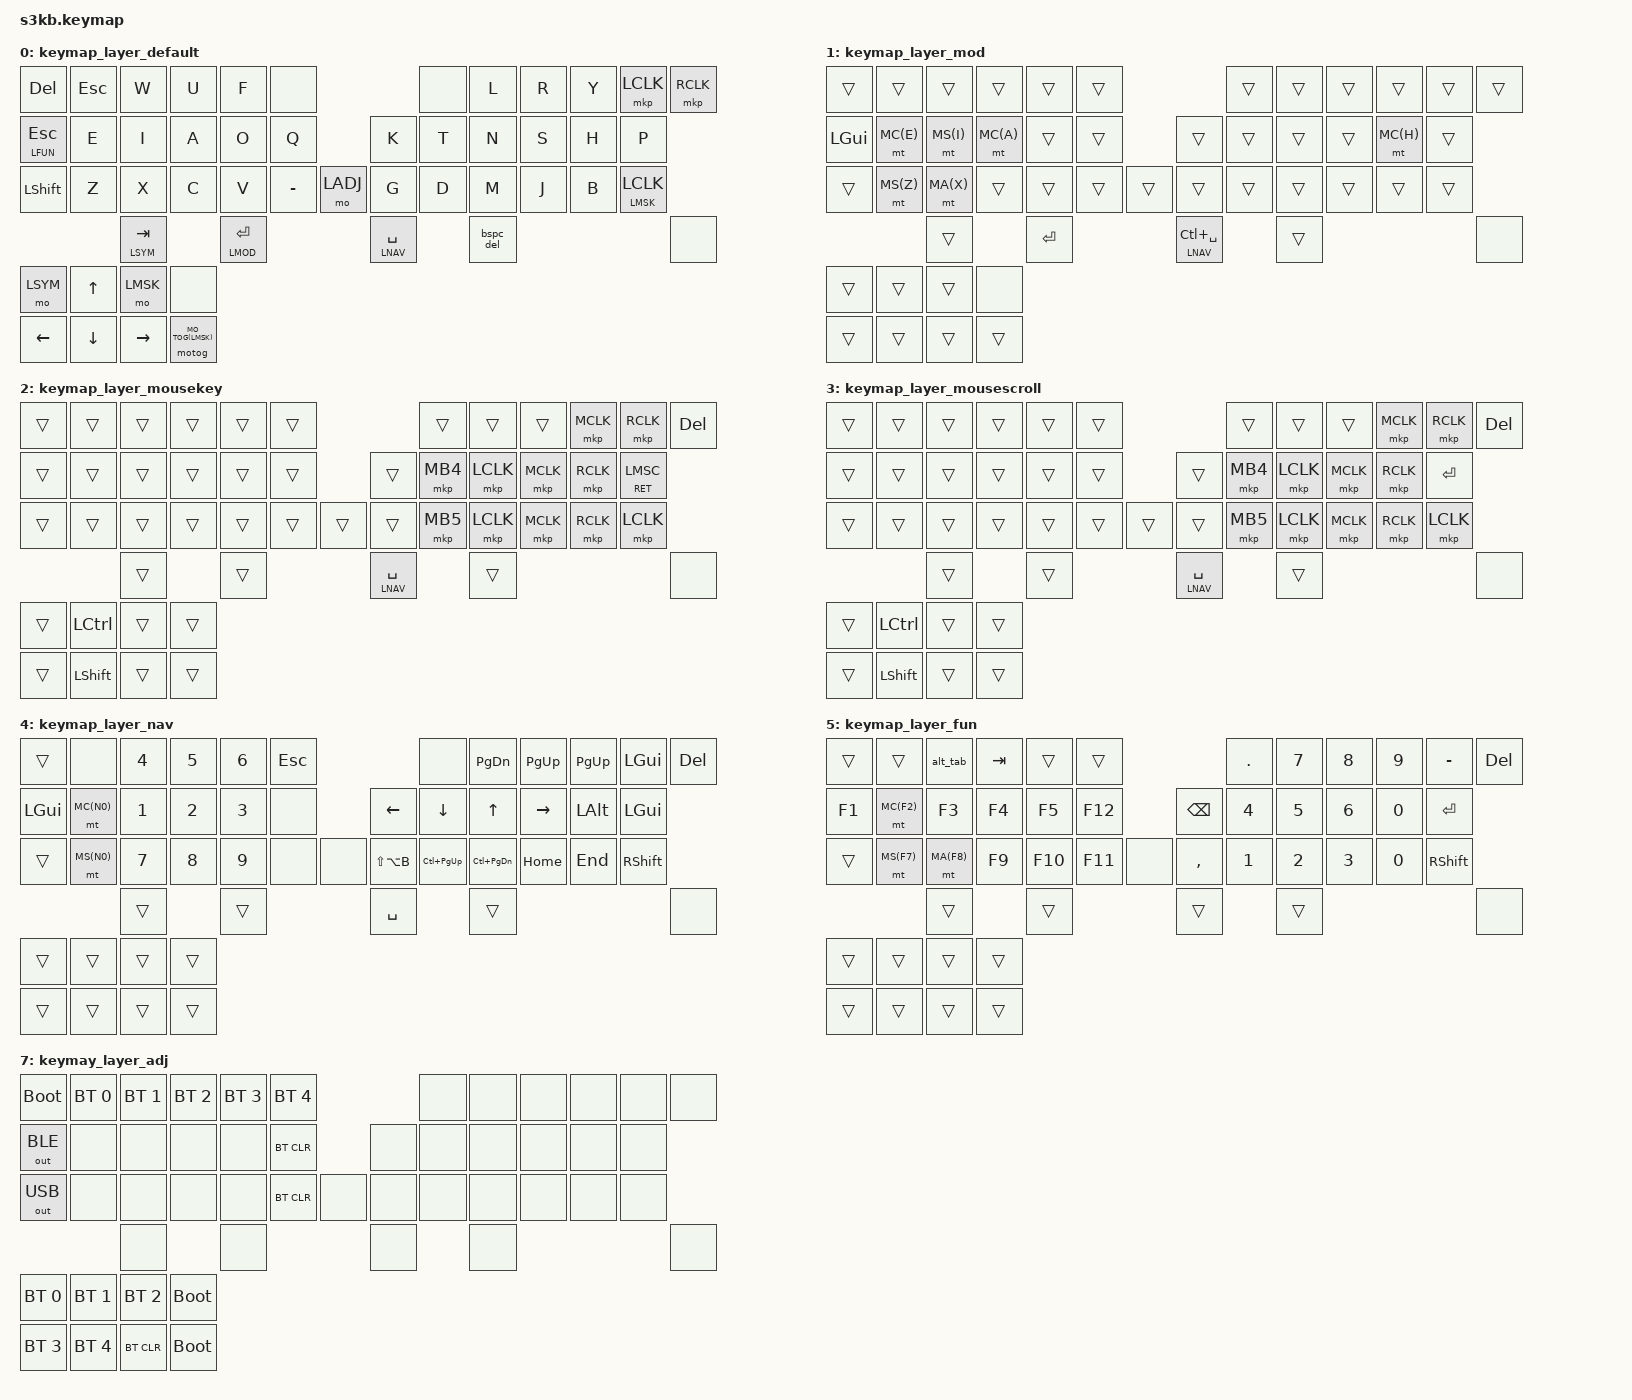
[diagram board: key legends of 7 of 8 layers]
#include <behaviors.dtsi>
#include <dt-bindings/zmk/keys.h>
#include <dt-bindings/zmk/bt.h>
#include <dt-bindings/zmk/outputs.h>
#include <dt-bindings/zmk/mouse.h>


/*
        ////////////////////
        // layer settings //
        ////////////////////
*/
#define LDEF 0
#define LMOD 1
#define LMSK 2
#define LMSC 3
#define LNAV 4
#define LFUN 5
#define LSYM 6
#define LADJ 7
/{
    keymap {
        compatible = "zmk,keymap";
        keymap_layer_default:keymap_layer_default{};
        keymap_layer_mod:keymap_layer_mod{};
        keymap_layer_mousekey:keymap_layer_mousekey{};
        keymap_layer_mousescroll:keymap_layer_mousescroll{};
        keymap_layer_nav:keymap_layer_nav{};
        keymap_layer_fun:keymap_layer_fun{};
        keymap_layer_sym:keymap_layer_sym{};
        keymay_layer_adj:keymay_layer_adj{};
    };
};


/*
        //////////////
        // encoders //
        //////////////
*/
/ {
    encoders: encoders {
        compatible = "zmk,keymap-sensors";
        sensors = <&left_encoder &mid_encoder &right_encoder>;
        left_config{
            triggers-per-rotation = <7>;
        };
        mid_config{
            triggers-per-rotation = <24>;
        };
        right_config{
            triggers-per-rotation = <24>;
        };
    };
};

// scroll behavior for encoder
#define ZMK_MOUSE_ENC_SCRL_VAL 70
#define SCRL_ENC_UP MOVE_Y(ZMK_MOUSE_ENC_SCRL_VAL)
#define SCRL_ENC_DOWN MOVE_Y(-ZMK_MOUSE_ENC_SCRL_VAL)
#define SCRL_ENC_LEFT MOVE_X(-ZMK_MOUSE_ENC_SCRL_VAL)
#define SCRL_ENC_RIGHT MOVE_X(ZMK_MOUSE_ENC_SCRL_VAL)
#define ZMK_MOUSE_ENC_SCRL_FAST_VAL 140
#define SCRL_ENC_FAST_UP MOVE_Y(ZMK_MOUSE_ENC_SCRL_FAST_VAL)
#define SCRL_ENC_FAST_DOWN MOVE_Y(-ZMK_MOUSE_ENC_SCRL_FAST_VAL)
#define SCRL_ENC_FAST_LEFT MOVE_X(-ZMK_MOUSE_ENC_SCRL_FAST_VAL)
#define SCRL_ENC_FAST_RIGHT MOVE_X(ZMK_MOUSE_ENC_SCRL_FAST_VAL)
/{
    behaviors{
        scroll_enc_du: scroll_enc_du {
            compatible = "zmk,behavior-sensor-rotate";
            #sensor-binding-cells = <0>;
            bindings = <&msc SCRL_ENC_DOWN>, <&msc SCRL_ENC_UP>;
            tap-ms = <20>;
        };
        scroll_enc_fast_du: scroll_enc_fast_du {
            compatible = "zmk,behavior-sensor-rotate";
            #sensor-binding-cells = <0>;
            bindings = <&msc SCRL_ENC_FAST_DOWN>, <&msc SCRL_ENC_FAST_UP>;
            tap-ms = <20>;
        };
        scroll_enc_rl: scroll_enc_rl {
            compatible = "zmk,behavior-sensor-rotate";
            #sensor-binding-cells = <0>;
            bindings = <&msc SCRL_ENC_RIGHT>, <&msc SCRL_ENC_LEFT>;
            tap-ms = <20>;
        };
    };
};

/*
        //////////////////////////
        // custom key behaviors //
        //////////////////////////
*/
// macro for mod tap
#define MC(X) LCTRL X
#define MS(X) LSHFT X
#define MA(X) LALT X
#define MG(X) LGUI X

&mt {
    tapping-term-ms = <175>;
    flavor = "tap-preferred";
};
&lt {
    tapping-term-ms = <175>;
    flavor = "balanced";
};
&sk {
    quick-release;
};
&caps_word {
    continue-list = <UNDERSCORE MINUS BACKSPACE>;
};
#define MO_TOG(X) X X
/ {
    behaviors {
        // original behaviors
        smo: sticky_key_and_mo {
            // &smo LFUN LSHFT : tap to sticky shift, hold to function layer
            compatible = "zmk,behavior-hold-tap";
            #binding-cells = <2>;
            flavor = "hold-preferred";
            tapping-term-ms = <200>;
            bindings = <&mo>, <&sk>;
        };
        bspc_del: bspc_and_del{
            compatible = "zmk,behavior-mod-morph";
            #binding-cells = <0>;
            bindings = <&kp BSPC>, <&kp DEL>;
            mods = <(MOD_LSFT|MOD_RSFT)>;
        };
 
        // behaviors for mouse
        motog: behavior_mo_tog {
            compatible = "zmk,behavior-hold-tap";
            #binding-cells = <2>;
            flavor = "hold-preferred";
            tapping-term-ms = <200>;
            bindings = <&mo>, <&tog>;
        };
        mlt: mouse_layer_tap {
            compatible = "zmk,behavior-hold-tap";
            #binding-cells = <2>;
            flavor = "tap-preferred";
            tapping-term-ms = <200>;
            bindings = <&mo>, <&mkp>;
        };

        // behaviors for mod layer
        lth: layer_tap_hold_flavor {
            compatible = "zmk,behavior-hold-tap";
            #binding-cells = <2>;
            flavor = "hold-preferred";
            tapping-term-ms = <200>;
            bindings = <&mo>, <&kp>;
        };
        lm: momentally_layer_and_modifier {
            // activate momentally layer and press (modifier) key
            // &lm LMOD LCTRL : activate modifier layer with LCTRL hold
            compatible = "zmk,behavior-macro-two-param";
            wait-ms = <0>;
            tap-ms = <0>;
            #binding-cells = <2>;
            bindings
                = <&macro_param_1to1>
                , <&macro_press &mo MACRO_PLACEHOLDER>
                , <&macro_param_2to1>
                , <&macro_press &kp MACRO_PLACEHOLDER>
                , <&macro_pause_for_release>
                , <&macro_param_2to1>
                , <&macro_release &kp MACRO_PLACEHOLDER>
                , <&macro_param_1to1>
                , <&macro_release &mo MACRO_PLACEHOLDER>
                ;
        };
    };
    macros {
        // alt+tab on tap, continue to press alt on hold. 
        alt_tab: alt_tab {
            compatible = "zmk,behavior-macro";
            #binding-cells = <0>;
            wait-ms = <0>;
            tap-ms = <0>;
            bindings
                = <&macro_press &kp LALT>
                , <&macro_tap &kp TAB>
                , <&macro_pause_for_release>
                , <&macro_release &kp LALT>
                ;
        };
    };
};



/*
        ////////////
        // combos //
        ////////////
*/
/{
    combos{
        compatible = "zmk,combos";
        timeout-ms = <200>;

        // key-position = row*7 + col
        //    RC(0,0) RC(0,1) RC(0,2) RC(0,3) RC(0,4) RC(0,5)         RC(0,6) RC(1,0) RC(1,1) RC(1,2) RC(1,3) RC(1,4)
        //    RC(1,5) RC(1,6) RC(2,0) RC(2,1) RC(2,2) RC(2,3)         RC(2,4) RC(2,5) RC(2,6) RC(3,0) RC(3,1) RC(3,2)
        //    RC(3,3) RC(3,4) RC(3,5) RC(3,6) RC(4,0) RC(4,1) RC(4,2) RC(4,3) RC(4,4) RC(4,5) RC(4,6) RC(5,0) RC(5,1)
        //                                    RC(5,2) RC(5,3)         RC(5,4) RC(5,5)                                   RC(5,6)

        combo_L_23T {
            key-positions = <2 3>;
            bindings = <&kp ESC>;
        };

        combo_right_2TM {
            key-positions = <7 19>;
            bindings = <&kp COMMA>;
        };
        combo_right_3TM {
            key-positions = <8 20>;
            bindings = <&kp DOT>;
        };
        combo_right_4TM {
            key-positions = <9 21>;
            bindings = <&kp SEMI>;
        };
        combo_right_456B {
            key-positions = <34 35 36>;
            bindings = <&mo LMSC>;
        };
        combo_right_56T {
            key-positions = <10 11>;
            bindings = <&mo LMSC>;
        };
        combo_R_23B {
            key-positions = <34 35>;
            bindings = <&kp PRCNT>;
            layers = < LDEF LMOD LNAV LSYM LADJ>;
        };


        // thum
        combo_L_thum {
            key-positions = <37 38>;
            bindings = <&smo LFUN LSHFT>;
        };
        combo_R_thum {
            key-positions = <39 40>;
            bindings = <&caps_word>;
        };

        // thum mod
        combo_L_1M_thum { // ctrl
            key-positions = <13 38>;
            bindings = <&lm LMOD LCTRL>;
            slow-release;
        };
        combo_L_1B_thum { // shift
            key-positions = <25 38>;
            bindings = <&lm LMOD LSHFT>;
            slow-release;
        };
        combo_L_0M_thum { // gui
            key-positions = <12 38>;
            bindings = <&lm LMOD LGUI>;
            slow-release;
        };
        combo_L_3M_thum { // ctrl
            key-positions = <15 38>;
            bindings = <&lm LMOD LCTRL>;
            slow-release;
        };

    };

};




/*
        /////////////
        // keymaps //
        /////////////
*/

&keymap_layer_default {
    bindings = <
    &kp DEL       &kp ESC &kp W &kp U &kp F &none                  &none &kp L &kp R &kp Y &mkp LCLK &mkp RCLK
    &lt LFUN ESC  &kp E   &kp I &kp A &kp O &kp Q                  &kp K &kp T &kp N &kp S &kp H &kp P
    &kp LSHFT     &kp Z   &kp X &kp C &kp V &kp MINUS  &mo LADJ    &kp G &kp D &kp M &kp J &kp B &mlt LMSK LCLK
                            &lt LSYM TAB &lth LMOD RET           &lt LNAV SPACE &bspc_del               &none
    &mo LSYM  &kp UP    &mo LMSK   &none
    &kp LEFT  &kp DOWN  &kp RIGHT  &motog MO_TOG(LMSK)
    >;
    /* cw-ccw = right-left = down-up */
    sensor-bindings = <&inc_dec_kp TAB LS(TAB) &inc_dec_kp RIGHT LEFT &scroll_enc_du >; 
};

&keymap_layer_mod {
    bindings = <
    &trans       &trans    &trans    &trans    &trans &trans            &trans &trans &trans &trans &trans &trans
    &kp LGUI     &mt MC(E) &mt MS(I) &mt MC(A) &trans &trans            &trans &trans &trans &trans &mt MC(H) &trans
    &trans       &mt MS(Z) &mt MA(X) &trans    &trans &trans  &trans    &trans &trans &trans &trans &trans &trans
                       &trans &kp RET                                   &lt LNAV LC(SPACE) &trans               &none
    &trans  &trans    &trans   &none
    &trans  &trans    &trans   &trans
    >;
    /* cw-ccw = right-left = down-up */
    sensor-bindings = <&inc_dec_kp TAB LS(TAB) &inc_dec_kp RIGHT LEFT &scroll_enc_du >; 
};

&keymap_layer_mousekey {
    bindings = <
    &trans &trans &trans &trans &trans &trans        &trans &trans   &trans    &mkp MCLK &mkp RCLK &kp DEL
    &trans &trans &trans &trans &trans &trans        &trans &mkp MB4 &mkp LCLK &mkp MCLK &mkp RCLK &lt RET LMSC
    &trans &trans &trans &trans &trans &trans &trans &trans &mkp MB5 &mkp LCLK &mkp MCLK &mkp RCLK &mkp LCLK 
                       &trans &trans                             &lt LNAV SPACE &trans               &none
    &trans &kp LCTRL &trans &trans
    &trans &kp LSHFT &trans &trans
    >;
    /* cw-ccw = right-left = down-up */
    sensor-bindings = <&scroll_enc_rl &scroll_enc_rl &scroll_enc_du >; 
};

&keymap_layer_mousescroll{
    bindings = <
    &trans &trans &trans &trans &trans &trans        &trans &trans   &trans    &mkp MCLK &mkp RCLK &kp DEL
    &trans &trans &trans &trans &trans &trans        &trans &mkp MB4 &mkp LCLK &mkp MCLK &mkp RCLK &kp RET 
    &trans &trans &trans &trans &trans &trans &trans &trans &mkp MB5 &mkp LCLK &mkp MCLK &mkp RCLK &mkp LCLK 
                       &trans &trans                             &lt LNAV SPACE &trans               &none
    &trans &kp LCTRL &trans &trans
    &trans &kp LSHFT &trans &trans
    >;
    /* cw-ccw = right-left = down-up */
    sensor-bindings = <&scroll_enc_rl &scroll_enc_rl &scroll_enc_du >; 
};

&keymap_layer_nav {
    bindings = <
    &trans    &none      &kp N4 &kp N5 &kp N6  &kp ESC         &none         &kp PG_DN     &kp PG_UP        &kp PG_UP    &kp LGUI &kp DEL 
    &kp LGUI  &mt MC(N0) &kp N1 &kp N2 &kp N3  &none           &kp LEFT &kp DOWN      &kp UP        &kp RIGHT &kp LALT &kp LGUI
    &trans    &mt MS(N0) &kp N7 &kp N8 &kp N9  &none    &none  &kp LS(LA(B)) &kp LC(PG_UP) &kp LC(PG_DN) &kp HOME     &kp END  &kp RSHFT
                       &trans &trans                             &kp SPACE &trans               &none
    &trans &trans &trans &trans
    &trans &trans &trans &trans
    >;
    /* cw-ccw = right-left = down-up */
    sensor-bindings = <&inc_dec_kp LC(PG_DN) LC(PG_UP) &inc_dec_kp DOWN UP &inc_dec_kp LC(PG_DN) LC(PG_UP) >; 
};

&keymap_layer_fun {
    bindings = <
    &trans   &trans     &alt_tab   &kp TAB &trans  &trans          &kp DOT    &kp N7 &kp N8 &kp N9 &kp MINUS &kp DEL 
    &kp F1   &mt MC(F2) &kp F3     &kp F4  &kp F5  &kp F12         &kp BSPC   &kp N4 &kp N5 &kp N6 &kp N0    &kp RET
    &trans   &mt MS(F7) &mt MA(F8) &kp F9  &kp F10 &kp F11         &none &kp COMMA  &kp N1 &kp N2 &kp N3 &kp N0    &kp RSHFT
                       &trans &trans                             &trans &trans               &none
    
    &trans &trans &trans &trans
    &trans &trans &trans &trans
    >;
    /* cw-ccw = right-left = down-up */
    sensor-bindings = <&inc_dec_kp C_VOL_DN C_VOL_UP &inc_dec_kp C_BRI_DEC C_BRI_INC &inc_dec_kp C_VOL_DN C_VOL_UP>;
};

&keymap_layer_sym {
    bindings = <
    &kp LALT   &kp TILDE      &kp AT   &kp HASH    &kp DLLR    &kp ESC             &kp RBRC    &kp AMPS    &kp STAR    &kp UNDER   &kp PLUS        &kp DEL 
    &kp LCTRL  &mt LCTRL EXCL &kp LBKT &kp LPAR    &kp COLON   &kp LBRC            &kp BSPC    &kp FSLH    &kp RPAR    &kp RBKT    &mt LCTRL EQUAL &kp RET
    &kp LSHFT  &kp GRAVE      &kp LT   &kp MINUS   &kp GT      &kp PIPE  &none     &kp CARET   &kp QMARK   &kp DQT     &kp SQT     &kp BSLH        &kp RSHFT
                                                    &trans      &kp LCTRL           &kp SPACE   &kp LGUI                  &none
                       &kp TAB &trans                             &trans &trans               &none
    
    &trans &trans &trans &trans
    &trans &trans &trans &trans
    >;
    /* cw-ccw = right-left = down-up */
    sensor-bindings = <&inc_dec_kp DOWN UP &inc_dec_kp DOWN UP &scroll_enc_fast_du>;
};

&keymay_layer_adj {
    bindings = <
    &bootloader  &bt BT_SEL 0 &bt BT_SEL 1 &bt BT_SEL 2 &bt BT_SEL 3 &bt BT_SEL 4       &none &none &none &none &none &none
    &out OUT_BLE &none        &none        &none        &none        &bt BT_CLR         &none &none &none &none &none &none       
    &out OUT_USB &none        &none        &none        &none        &bt BT_CLR   &none &none &none &none &none &none &none            
                                                        &none      &none                &none &none                         &none
    &bt BT_SEL 0 &bt BT_SEL 1 &bt BT_SEL 2 &bootloader
    &bt BT_SEL 3 &bt BT_SEL 4 &bt BT_CLR   &bootloader
    >;
    sensor-bindings = <&inc_dec_kp C_VOL_DN C_VOL_UP &inc_dec_kp C_BRI_DEC C_BRI_INC &inc_dec_kp C_VOL_DN C_VOL_UP>;
};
